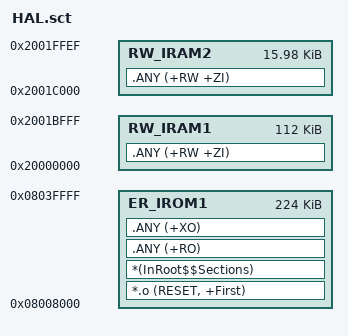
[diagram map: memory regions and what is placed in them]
; ******************************************************************
; *** Scatter-Loading Description File generated by Embedded IDE ***
; ******************************************************************

LR_IROM1 0x08008000 0x00038000 {
	ER_IROM1 0x08008000 0x00038000 {
		*.o (RESET, +First) 
		*(InRoot$$Sections) 
		.ANY (+RO) 
		.ANY (+XO) 
	}
	RW_IRAM1 0x20000000 0x0001C000 {
		.ANY (+RW +ZI) 
	}
	RW_IRAM2 0x2001C000 0x00003FF0 {
		.ANY (+RW +ZI) 
	}
}

